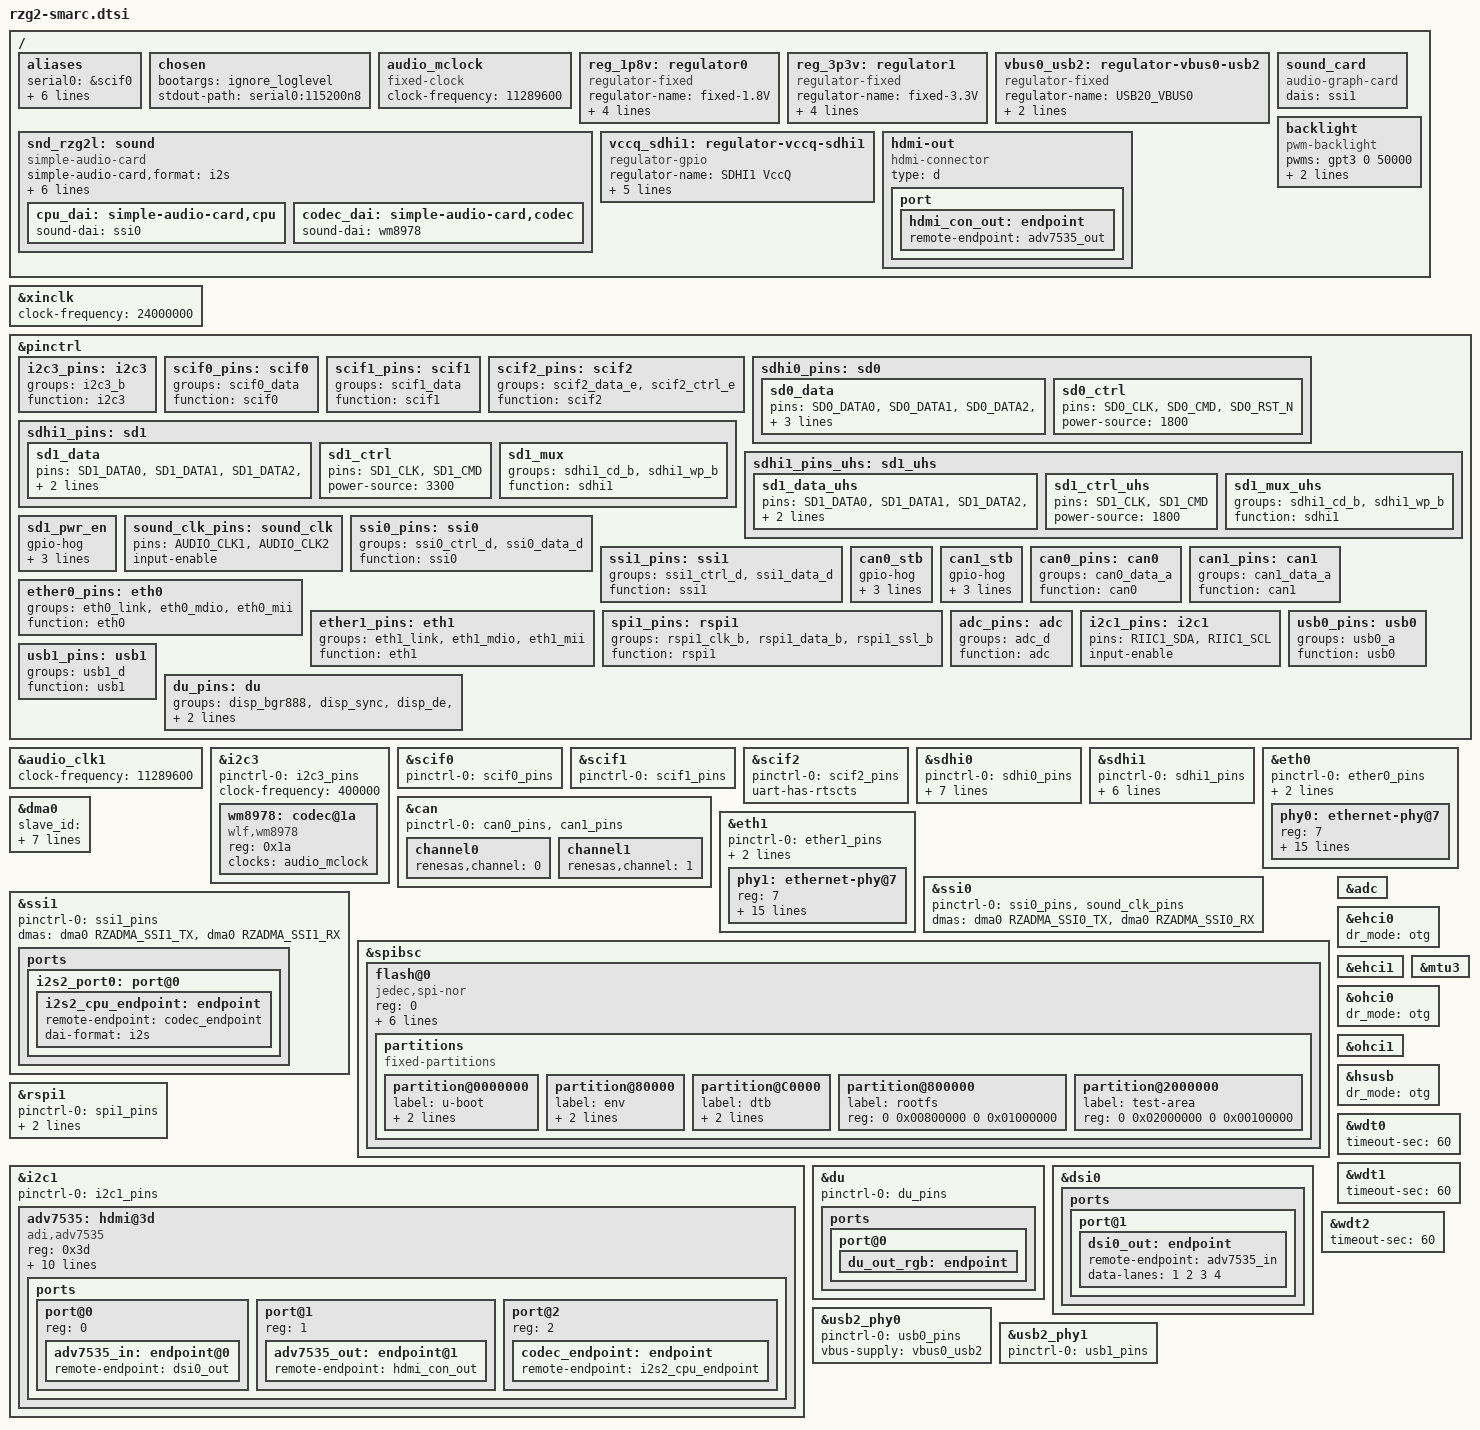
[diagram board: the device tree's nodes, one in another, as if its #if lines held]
// SPDX-License-Identifier: GPL-2.0
/*
 * Device Tree Source for the RZG2 SMARC main board common parts
 *
 * Copyright (C) 2020 Renesas Electronics Corp.
 */

#include <dt-bindings/pinctrl/pinctrl-rzg2l.h>
#include <dt-bindings/gpio/gpio.h>

/*
 * SSI-WM8978
 *
 * This command is required when Playback/Capture
 *
 *	amixer cset name='Left Input Mixer L2 Switch' on
 *	amixer cset name='Right Input Mixer R2 Switch' on
 *	amixer cset name='Headphone Playback Volume' 100
 *	amixer cset name='PCM Volume' 100%
 *	amixer cset name='Input PGA Volume' 25
 *
 * ADV7535 Audio playback
 *	aplay -D hw:1,0 xxx.wav
 */

/* Select one funtion support SDHI1|GPT (1: enabled, 0 : disabled)
 * SDHI1 and GPT have pin conflict. Only one can be enabled at once
 */
#define SDHI1_SUPPORT		1
#define GPT_SUPPORT		0

/* Enable/Disable CAN support (must choose 1) */
#define CAN_SUPPORT		1
//#define CAN_SUPPORT		0

/* With above CAN selection, we will get all below results */
#if (CAN_SUPPORT)
/* Parallel display is disabled due to pins conflict with CAN.
 * Therefore, we must set 0 to Parallel display macros like below.
 */
#define DISP_PARALLEL_HDMI	0
#define DISP_PARALLEL_PANEL	0

/* Besides that, LCDC can only output 1 video interface (Parallel or MIPI DSI).
 * Because parallel display is disabled as above, we enable MIPI DSI as below.
 * Please choose one of two interfaces (HDMI or panel) based on your board
 * by setting 1 in value.
 * Currently we support HDMI as default output.
 */
#define DISP_DSI_HDMI		1
#define DISP_DSI_PANEL		0

/* CAN and ADC hardware Trigger have pin conflict.
 * When Can is enabled, disable ADC_HWTRG_SUPPORT
 */
#define ADC_HWTRG_SUPPORT		0
#else
/* Parallel display is supported as default if not support CAN.
 * Please choose one of two interfaces (HDMI or panel) based on your board
 * by setting 1 in value.
 * Currently we support HDMI as default output.
 */
#define DISP_PARALLEL_HDMI	1
#define DISP_PARALLEL_PANEL	0

/* MIPI DSI is disabled when Parallel display support.
 * Must disabled by setting 0 as below macros.
 */
#define DISP_DSI_HDMI		0
#define DISP_DSI_PANEL		0

/* CAN and ADC hardware Trigger have pin conflict.
 * When Can is disabled, enable ADC_HWTRG_SUPPORT
 */
#define ADC_HWTRG_SUPPORT		1
#endif

/* Below macros are created to check which video interface is supporting
 * and notify error if:
 * - Support both Parallel display and MIPI DSI at the same time.
 * - Support CAN and Parallel display at the same time.
 */
#define DISP_PARALLEL		(DISP_PARALLEL_HDMI | DISP_PARALLEL_PANEL)
#define DISP_DSI		(DISP_DSI_HDMI | DISP_DSI_PANEL)
#define DISP_HDMI		(DISP_PARALLEL_HDMI | DISP_DSI_HDMI)
#define DISP_PANEL		(DISP_PARALLEL_PANEL | DISP_DSI_PANEL)

#if (CAN_SUPPORT & DISP_PARALLEL)
#error "RZ/G2L can not enable CAN and Parallel display simultaneously"
#endif

#if ((DISP_PARALLEL & DISP_DSI) || (DISP_HDMI & DISP_PANEL))
#error "RZ/G2L can only display 1 output interface"
#endif

/ {
	aliases {
		serial0 = &scif0;
		serial1 = &scif1;
		serial2 = &scif2;
#if (CAN_SUPPORT)
		can0 = &can;
		can1 = &can;
#endif
		ethernet0 = &eth0;
		ethernet1 = &eth1;
	};

	chosen {
		bootargs = "ignore_loglevel";
		stdout-path = "serial0:115200n8";
	};

	audio_mclock: audio_mclock {
		compatible = "fixed-clock";
		#clock-cells = <0>;
		clock-frequency = <11289600>;
	};

	reg_1p8v: regulator0 {
		compatible = "regulator-fixed";

		regulator-name = "fixed-1.8V";
		regulator-min-microvolt = <1800000>;
		regulator-max-microvolt = <1800000>;
		regulator-boot-on;
		regulator-always-on;
	};

	reg_3p3v: regulator1 {
		compatible = "regulator-fixed";

		regulator-name = "fixed-3.3V";
		regulator-min-microvolt = <3300000>;
		regulator-max-microvolt = <3300000>;
		regulator-boot-on;
		regulator-always-on;
	};

	vbus0_usb2: regulator-vbus0-usb2 {
		compatible = "regulator-fixed";

		regulator-name = "USB20_VBUS0";
		regulator-min-microvolt = <5000000>;
		regulator-max-microvolt = <5000000>;
	};

	snd_rzg2l: sound {
		compatible = "simple-audio-card";
		simple-audio-card,format = "i2s";
		simple-audio-card,bitclock-master = <&cpu_dai>;
		simple-audio-card,frame-master = <&cpu_dai>;

		simple-audio-card,widgets = "Microphone", "Microphone Jack";
		simple-audio-card,routing =
			    "L2", "Mic Bias",
			    "R2", "Mic Bias",
			    "Mic Bias", "Microphone Jack";

		cpu_dai: simple-audio-card,cpu {
			sound-dai = <&ssi0>;
		};

		codec_dai: simple-audio-card,codec {
			sound-dai = <&wm8978>;
		};
	};

#if (DISP_DSI_HDMI)
	sound_card {
		compatible = "audio-graph-card";
		dais = <&ssi1>;
	};
#endif

	vccq_sdhi1: regulator-vccq-sdhi1 {
		compatible = "regulator-gpio";

		regulator-name = "SDHI1 VccQ";
		regulator-min-microvolt = <1800000>;
		regulator-max-microvolt = <3300000>;

		gpios = <&pinctrl RZG2L_GPIO(39, 1) GPIO_ACTIVE_HIGH>;

		gpios-states = <1>;
		states = <3300000 0
			  1800000 1>;
	};

/* Read Only File system in QSPI Example */
/* File System in XIP QSPI */
/* Remember, we'll be in QSPI XIP mode at this point */
/* Requires CONFIG_MTD_ROM=y */
	qspi@20000000 {
		compatible = "mtd-rom";
		//probe-type = "map_rom";
		probe-type = "direct-mapped";   // XIP from QSPI
		reg = <0 0x20000000 0 0x4000000>;   /* 64 MB*/
		bank-width = <4>;
		device-width = <1>;
		
		#address-cells = <1>;
		#size-cells = <1>;
		
		partition@800000 {
			label ="rootfs_xipcramfs";
			reg = <0x0800000 0x1000000>; /* 16MB @ 0x20800000 */
			read-only;
		};
	};

	backlight {
		compatible = "pwm-backlight";
		pwms = <&gpt3 0 50000>;

		brightness-levels = <0 2 8 16 32 64 128 255>;
		default-brightness-level = <6>;
	};

#if (DISP_HDMI)
	hdmi-out {
		compatible = "hdmi-connector";
		type = "d";

		port {
			hdmi_con_out: endpoint {
#if (DISP_DSI_HDMI)
				remote-endpoint = <&adv7535_out>;
#endif
#if (DISP_PARALLEL_HDMI)
				remote-endpoint = <&adv7513_out>;
#endif
			};
		};
	};
#endif
};

&xinclk {
	clock-frequency = <24000000>;
};

&pinctrl {
	i2c3_pins: i2c3 {
		groups = "i2c3_b";
		function = "i2c3";
	};

	scif0_pins: scif0 {
		groups = "scif0_data";
		function = "scif0";
	};

	scif1_pins: scif1 {
		groups = "scif1_data";
		function = "scif1";
	};

	scif2_pins: scif2 {
		groups = "scif2_data_e", "scif2_ctrl_e" ;
		function = "scif2";
	};

	sdhi0_pins: sd0 {
		sd0_data {
			pins =  "SD0_DATA0", "SD0_DATA1", "SD0_DATA2",
				"SD0_DATA3", "SD0_DATA4", "SD0_DATA5",
				"SD0_DATA6", "SD0_DATA7";
			power-source  = <1800>;
		};

		sd0_ctrl {
			pins = "SD0_CLK", "SD0_CMD", "SD0_RST_N";
			power-source = <1800>;
		};
	};

#if (SDHI1_SUPPORT)
	sdhi1_pins: sd1 {
		sd1_data {
			pins =	"SD1_DATA0", "SD1_DATA1", "SD1_DATA2",
				"SD1_DATA3";
			power-source  = <3300>;
		};

		sd1_ctrl {
			pins = "SD1_CLK", "SD1_CMD";
			power-source  = <3300>;
		};

		sd1_mux {
			groups = "sdhi1_cd_b", "sdhi1_wp_b";
			function = "sdhi1";
		};
	};

	sdhi1_pins_uhs: sd1_uhs {
		sd1_data_uhs {
			pins =	"SD1_DATA0", "SD1_DATA1", "SD1_DATA2",
				"SD1_DATA3";
			power-source  = <1800>;
		};

		sd1_ctrl_uhs {
			pins = "SD1_CLK", "SD1_CMD";
			power-source  = <1800>;
		};

		sd1_mux_uhs {
			groups = "sdhi1_cd_b", "sdhi1_wp_b";
			function = "sdhi1";
		};
	};

	sd1_pwr_en {
		gpio-hog;
		gpios = <RZG2L_GPIO(39, 2) GPIO_ACTIVE_HIGH>;
		output-high;
		line-name = "sd1_pwr_en";
	};
#endif

	sound_clk_pins: sound_clk {
		pins = "AUDIO_CLK1", "AUDIO_CLK2";
		input-enable;
	};

	ssi0_pins: ssi0 {
		groups = "ssi0_ctrl_d", "ssi0_data_d";
		function = "ssi0";
	};

#if (DISP_DSI_HDMI)
	ssi1_pins: ssi1 {
		groups = "ssi1_ctrl_d", "ssi1_data_d";
		function = "ssi1";
	};
#endif

#if (CAN_SUPPORT)
	can0_stb {
		gpio-hog;
		gpios = <RZG2L_GPIO(42, 2) GPIO_ACTIVE_LOW>;
		output-high;
		line-name = "can0_stb";
	};

	can1_stb {
		gpio-hog;
		gpios = <RZG2L_GPIO(42, 3) GPIO_ACTIVE_LOW>;
		output-high;
		line-name = "can1_stb";
	};

	can0_pins: can0 {
		groups = "can0_data_a";
		function = "can0";
	};

	can1_pins: can1 {
		groups = "can1_data_a";
		function = "can1";
	};
#endif

	ether0_pins: eth0 {
		groups = "eth0_link", "eth0_mdio", "eth0_mii";
		function = "eth0";
	};
	
	ether1_pins: eth1 {
		groups = "eth1_link", "eth1_mdio", "eth1_mii";
		function = "eth1";
	};

	spi1_pins: rspi1 {
		groups = "rspi1_clk_b", "rspi1_data_b", "rspi1_ssl_b";
		function = "rspi1";
	};

#if (GPT_SUPPORT)
	gpt3_pins: gpt3 {
		groups = "gpt3_b_b";
		function = "gpt3";
	};
#endif

	adc_pins: adc {
		groups = "adc_d";
		function = "adc";
	};

	i2c1_pins: i2c1 {
		pins = "RIIC1_SDA", "RIIC1_SCL";
		input-enable;
	};

	usb0_pins: usb0 {
		groups = "usb0_a";
		function = "usb0";
	};

	usb1_pins: usb1 {
		groups = "usb1_d";
		function = "usb1";
	};

#if (DISP_PARALLEL)
	du_pins: du {
		groups = "disp_bgr888", "disp_sync", "disp_de", "disp_clk";
		function = "disp";
	};
#endif
};

&audio_clk1{
	clock-frequency = <11289600>;
};

&i2c3 {
	pinctrl-0 = <&i2c3_pins>;
	pinctrl-names = "default";

	status = "okay";
	clock-frequency = <400000>;

	wm8978: codec@1a {
		compatible = "wlf,wm8978";
		#sound-dai-cells = <0>;
		reg = <0x1a>;
		clocks = <&audio_mclock>;
		clock-names = "mclk";
	};
};

&scif0 {
	pinctrl-0 = <&scif0_pins>;
	pinctrl-names = "default";
	status = "okay";
};

&scif1 {
	pinctrl-0 = <&scif1_pins>;
	pinctrl-names = "default";
	status = "okay";
};

&scif2 {
	pinctrl-0 = <&scif2_pins>;
	pinctrl-names = "default";
	uart-has-rtscts;
	status = "okay";
};

&sdhi0 {
	pinctrl-0 = <&sdhi0_pins>;
	pinctrl-1 = <&sdhi0_pins>;
	pinctrl-names = "default", "state_uhs";

	vmmc-supply = <&reg_3p3v>;
	vqmmc-supply = <&reg_1p8v>;
	bus-width = <8>;
	mmc-hs200-1_8v;
	non-removable;
	fixed-emmc-driver-type = <1>;
	status = "okay";
};

#if (SDHI1_SUPPORT)
&sdhi1 {
	pinctrl-0 = <&sdhi1_pins>;
	pinctrl-1 = <&sdhi1_pins_uhs>;
	pinctrl-names = "default", "state_uhs";

	vmmc-supply = <&reg_3p3v>;
	vqmmc-supply = <&vccq_sdhi1>;

	bus-width = <4>;
	sd-uhs-sdr50;
	sd-uhs-sdr104;
	status = "okay";
};
#endif

#if (CAN_SUPPORT)
&can {
	pinctrl-0 = <&can0_pins &can1_pins>;
	pinctrl-names = "default";
	status = "okay";
	channel0 {
		renesas,channel = <0>;
		status = "okay";
	};
	channel1 {
		renesas,channel = <1>;
		status = "okay";
	};
};
#endif

&eth0 {
	pinctrl-0 = <&ether0_pins>;
	pinctrl-names = "default";
	phy-handle = <&phy0>;
	phy-mode = "rgmii";
	status = "okay";

	phy0: ethernet-phy@7 {
		reg = <7>;
		rxc-skew-psec = <2400>;
		txc-skew-psec = <2400>;
		rxdv-skew-psec = <0>;
		txdv-skew-psec = <0>;
		rxd0-skew-psec = <0>;
		rxd1-skew-psec = <0>;
		rxd2-skew-psec = <0>;
		rxd3-skew-psec = <0>;
		txd0-skew-psec = <0>;
		txd1-skew-psec = <0>;
		txd2-skew-psec = <0>;
		txd3-skew-psec = <0>;

		interrupt-parent = <&pinctrl>;
		interrupts = <RZG2L_GPIO(1, 0) IRQ_TYPE_EDGE_FALLING>;
	};
};

&eth1 {
	pinctrl-0 = <&ether1_pins>;
	pinctrl-names = "default";
	phy-handle = <&phy1>;
	phy-mode = "rgmii";
	status = "okay";
	
	phy1: ethernet-phy@7 {
		reg = <7>;
		rxc-skew-psec = <2400>;
		txc-skew-psec = <2400>;
		rxdv-skew-psec = <0>;
		txdv-skew-psec = <0>;
		rxd0-skew-psec = <0>;
		rxd1-skew-psec = <0>;
		rxd2-skew-psec = <0>;
		rxd3-skew-psec = <0>;
		txd0-skew-psec = <0>;
		txd1-skew-psec = <0>;
		txd2-skew-psec = <0>;
		txd3-skew-psec = <0>;

		interrupt-parent = <&pinctrl>;
		interrupts = <RZG2L_GPIO(1, 1) IRQ_TYPE_EDGE_FALLING>;
	};
};

/* Delete our XIP QSPI partitions from the top of this file. You would not have these for non-XIP systems */
/ {
	/delete-node/ qspi@20000000;
};

/* Assign IDs to DMA channels (actual number is not important) */
#define RZADMA_SSI0_TX	1
#define RZADMA_SSI0_RX	2
#define RZADMA_SSI1_TX	3
#define RZADMA_SSI1_RX	4
#define RZADMA_RSPI1_TX	5
#define RZADMA_RSPI1_RX	6

/* DMA Configuration */
&dma0  {
	/* Assign Slave IDs */
	slave_id = <RZADMA_SSI0_TX
		    RZADMA_SSI0_RX
		    RZADMA_SSI1_TX
		    RZADMA_SSI1_RX
		    RZADMA_RSPI1_TX
		    RZADMA_RSPI1_RX>;
	/* Address of data source/destination */
	addr = <0x10049C18	/* SSIFTDR_0 */
		0x10049C1C	/* SSIFRDR_0 */
		0x1004A018	/* SSIFTDR_1 */
		0x1004A01C	/* SSIFRDR_1 */
		0x1004B004	/* SPDR_1 */
		0x1004B004	/* SPDR_1 */
		>;
	/* Channel Configuration Register (CHCFG) for slave device */
	/* .reqd .loen .hien .lvl .am .sds .dds .tm */
	chcfg = <0x1 0x0 0x1 0x0 0x2 0x1 0x1 0x0	/* SSI ch0 TX (req sig=SSIFTDR_0) */
		 0x0 0x0 0x1 0x0 0x2 0x1 0x1 0x0	/* SSI ch0 RX (req sig=SSIFRDR_0) */
		 0x1 0x0 0x1 0x0 0x2 0x1 0x1 0x0	/* SSI ch1 TX (req sig=SSIFTDR_0) */
		 0x0 0x0 0x1 0x0 0x2 0x1 0x1 0x0	/* SSI ch1 RX (req sig=SSIFRDR_0) */
		 0x1 0x0 0x1 0x1 0x2 0x0 0x0 0x0	/* RSPI1 TX (SPDR_1) */
		 0x0 0x0 0x1 0x1 0x2 0x0 0x0 0x0	/* RSPI1 RX (SPDR_1) */
		 >;
	/* DMARS for slave device */
	/* .rid .mid */
	dmars = <0x1 0x95	/* SSI ch0 TX */
		 0x2 0x95	/* SSI ch0 RX */
		 0x1 0x96	/* SSI ch1 TX */
		 0x2 0x96	/* SSI ch1 RX */
		 0x1 0xA6	/* RSPI ch1 TX */
		 0x2 0xA6	/* RSPI ch1 RX */
		 >;
};

&ssi0 {
	pinctrl-0 = <&ssi0_pins &sound_clk_pins>;
	pinctrl-names = "default";

	dmas = <&dma0 RZADMA_SSI0_TX>,
	       <&dma0 RZADMA_SSI0_RX>;
	dma-names = "tx", "rx";

	status = "okay";
};

#if (DISP_DSI_HDMI)
&ssi1 {
	pinctrl-0 = <&ssi1_pins>;
	pinctrl-names = "default";

	dmas = <&dma0 RZADMA_SSI1_TX>,
	       <&dma0 RZADMA_SSI1_RX>;
	dma-names = "tx", "rx";
	status = "okay";
	ports {
		i2s2_port0: port@0 {
			i2s2_cpu_endpoint: endpoint {
				remote-endpoint = <&codec_endpoint>;
				dai-format = "i2s";
			};
		};
	};
};
#endif

&spibsc {
	status = "okay";

	flash@0 {
		compatible = "jedec,spi-nor";
		reg = <0>;
		spi-max-frequency = <30000000>;

		spi-tx-bus-width = <4>;
		spi-rx-bus-width = <4>;

		/* SPI Mode 3 */
		spi-cpol;
		spi-cpha;
		m25p,fast-read;

		partitions {
			compatible = "fixed-partitions";
			#address-cells = <2>;
			#size-cells = <2>;

			partition@0000000 {
				label = "u-boot";
				reg = <0 0x00000000 0 0x80000>;
				read-only;
			};
			partition@80000 {
				label = "env";
				reg = <0 0x00080000 0 0x40000>;
				read-only;
			};
			partition@C0000 {
				label = "dtb";
				reg = <0 0x000C0000 0 0x40000>;
				read-only;
			};
			partition@800000 {
				label = "rootfs";
				/* 16MB @ 8MB offset in SPI Flash */
				reg = <0 0x00800000 0 0x01000000>;
			};
			partition@2000000 {
				label = "test-area";
				reg = <0 0x02000000 0 0x00100000>;
			};
		};
	};
};

&rspi1 {
	pinctrl-0 = <&spi1_pins>;
	pinctrl-names = "default";
	status = "okay";
	dmas = <&dma0 RZADMA_RSPI1_TX>,
	       <&dma0 RZADMA_RSPI1_RX>;
	dma-names = "tx", "rx";
};

#if (GPT_SUPPORT)
&gpt3 {
	pinctrl-0 = <&gpt3_pins>;
	pinctrl-names = "default";
	channel="channel_B";
	//conflict pin with SD1 WP
	status = "okay";
};
#endif

&adc {
#if (ADC_HWTRG_SUPPORT)
	//conflict pin with CAN0 pin
	pinctrl-0 = <&adc_pins>;
#endif
	pinctrl-names = "default";
	status = "okay";
};

&i2c1 {
	pinctrl-0 = <&i2c1_pins>;
	pinctrl-names = "default";

	status = "okay";

#if (DISP_DSI_HDMI)
	adv7535: hdmi@3d {
		compatible = "adi,adv7535";
		reg = <0x3d>;

		avdd-supply = <&reg_1p8v>;
		dvdd-supply = <&reg_1p8v>;
		pvdd-supply = <&reg_1p8v>;
		a2vdd-supply = <&reg_1p8v>;
		v3p3-supply = <&reg_3p3v>;
		v1p2-supply = <&reg_1p8v>;

		interrupt-parent = <&pinctrl>;
		interrupts = <RZG2L_GPIO(2, 1) IRQ_TYPE_EDGE_FALLING>;

		adi,dsi-lanes = <4>;
		#sound-dai-cells = <0>;

		ports {
			#address-cells = <1>;
			#size-cells = <0>;

			port@0 {
				reg = <0>;
				adv7535_in: endpoint@0 {
					remote-endpoint = <&dsi0_out>;
				};
			};

			port@1 {
				reg = <1>;
				adv7535_out: endpoint@1 {
					remote-endpoint = <&hdmi_con_out>;
				};
			};

			port@2 {
				reg = <2>;
				codec_endpoint: endpoint {
					remote-endpoint = <&i2s2_cpu_endpoint>;
				};
			};
		};
	};
#endif

#if (DISP_PARALLEL_HDMI)
	adv7513: adv7513@39 {
		compatible = "adi,adv7513";
		reg = <0x39>;

		adi,input-depth = <8>;
		adi,input-colorspace = "rgb";
		adi,input-clock = "1x";

		avdd-supply = <&reg_1p8v>;
		dvdd-supply = <&reg_1p8v>;
		pvdd-supply = <&reg_1p8v>;
		dvdd-3v-supply = <&reg_3p3v>;
		bgvdd-supply = <&reg_1p8v>;

		ports {
			#address-cells = <1>;
			#size-cells = <0>;

			port@0 {
				reg = <0>;

				adv7513_in: endpoint {
					remote-endpoint = <&du_out_rgb>;
				};
			};

			port@1 {
				reg = <1>;

				adv7513_out: endpoint {
					remote-endpoint = <&hdmi_con_out>;
				};
			};
		};
	};
#endif
};

&du {
#if (DISP_PARALLEL)
	pinctrl-0 = <&du_pins>;
	pinctrl-names = "default";
#endif
	status = "okay";

	ports {
		port@0 {
			du_out_rgb: endpoint {
#if (DISP_PARALLEL_HDMI)
				remote-endpoint = <&adv7513_in>;
#endif
			};
		};
	};
};

#if (DISP_DSI)
&dsi0 {
	status = "okay";

	ports {
		port@1 {
			dsi0_out: endpoint {
#if (DISP_DSI_HDMI)
				remote-endpoint = <&adv7535_in>;
				data-lanes = <1 2 3 4>;
#endif
			};
		};
	};
};
#endif

&ehci0 {
	dr_mode = "otg";
	status = "okay";
};

&ehci1 {
	status = "okay";
};

&mtu3 {
	status = "okay";
};

&ohci0 {
	dr_mode = "otg";
	status = "okay";
};

&ohci1 {
	status = "okay";
};

&hsusb {
	dr_mode = "otg";
	status = "okay";
};

&usb2_phy0 {
	pinctrl-0 = <&usb0_pins>;
	pinctrl-names = "default";

	vbus-supply = <&vbus0_usb2>;
	status = "okay";
};

&usb2_phy1 {
	pinctrl-0 = <&usb1_pins>;
	pinctrl-names = "default";

	status = "okay";
};

&wdt0 {
	status = "okay";
	timeout-sec = <60>;
};

&wdt1 {
	status = "okay";
	timeout-sec = <60>;
};

&wdt2 {
	status = "okay";
	timeout-sec = <60>;
};
